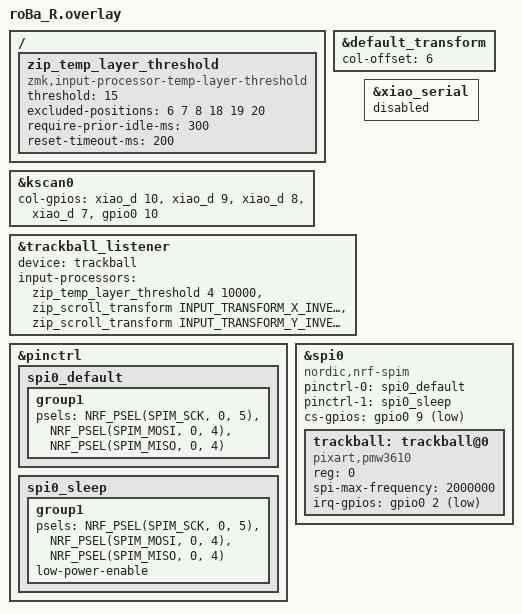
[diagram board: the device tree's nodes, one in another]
/*
 * roBa 右手側（トラックボール側）のデバイスツリー設定
 * - トラックボール (PMW3610)
 * - オートマウスレイヤー (zip_temp_layer_threshold)
 */

#include "roBa.dtsi"
#include <input/processors.dtsi>
#include <dt-bindings/zmk/input_transform.h>

&default_transform {
    col-offset = <6>;
};

&kscan0 {
        col-gpios
            = <&xiao_d 10 GPIO_ACTIVE_HIGH>
            , <&xiao_d 9 GPIO_ACTIVE_HIGH>
            , <&xiao_d 8 GPIO_ACTIVE_HIGH>
            , <&xiao_d 7 GPIO_ACTIVE_HIGH>
            , <&gpio0 10 GPIO_ACTIVE_HIGH>
            ;
};

/ {
    zip_temp_layer_threshold: zip_temp_layer_threshold {
        compatible = "zmk,input-processor-temp-layer-threshold";
        #input-processor-cells = <2>;
        
        // AML発動に必要な累積移動量
        threshold = <15>;
        
        // 以下で指定したキー以外を押すとAML解除
        excluded-positions = <
            6 // u
            7 // i
            8 // o
            18 // j
            19 // k
            20 // l
        >;

        // キー入力から300ms間はAMLを発動しない
        require-prior-idle-ms = <300>;
        
        // 蓄積された移動量をリセットするまでの時間
        reset-timeout-ms = <200>;
    };
};

&trackball_listener {
    status = "okay";
    device = <&trackball>;
    input-processors = <
        &zip_temp_layer_threshold 4 10000
        &zip_scroll_transform INPUT_TRANSFORM_X_INVERT
        &zip_scroll_transform INPUT_TRANSFORM_Y_INVERT
    >;
};

&pinctrl {
    spi0_default: spi0_default {
        group1 {
            psels = <NRF_PSEL(SPIM_SCK, 0, 5)>,
                <NRF_PSEL(SPIM_MOSI, 0, 4)>,
                <NRF_PSEL(SPIM_MISO, 0, 4)>;
        };
    };

    spi0_sleep: spi0_sleep {
        group1 {
            psels = <NRF_PSEL(SPIM_SCK, 0, 5)>,
                <NRF_PSEL(SPIM_MOSI, 0, 4)>,
                <NRF_PSEL(SPIM_MISO, 0, 4)>;
            low-power-enable;
        };
    };
};

&xiao_serial { status = "disabled"; };

&spi0 {
    status = "okay";
    compatible = "nordic,nrf-spim";
    pinctrl-0 = <&spi0_default>;
    pinctrl-1 = <&spi0_sleep>;
    pinctrl-names = "default", "sleep";
    cs-gpios = <&gpio0 9 GPIO_ACTIVE_LOW>;

    trackball: trackball@0 {
        status = "okay";
        compatible = "pixart,pmw3610";
        reg = <0>;
        spi-max-frequency = <2000000>;
        irq-gpios = <&gpio0 2 (GPIO_ACTIVE_LOW | GPIO_PULL_UP)>;
    };
};
